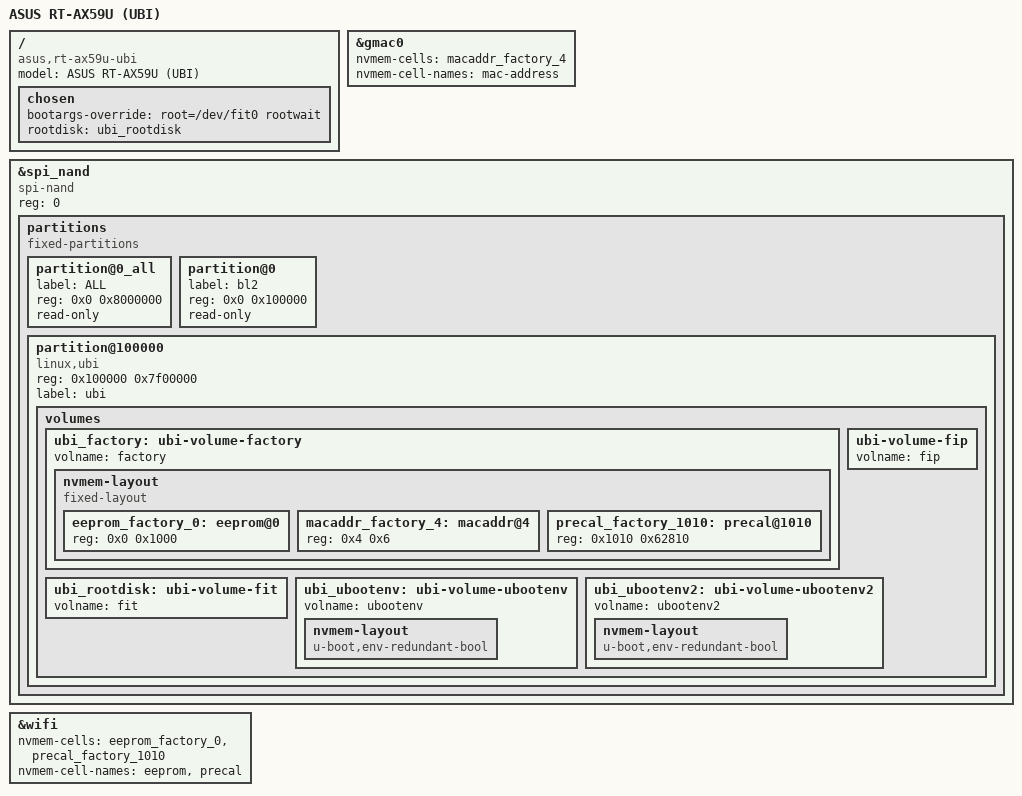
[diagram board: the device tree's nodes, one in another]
// SPDX-License-Identifier: (GPL-2.0 OR MIT)

#include "mt7986a-asus-rt-ax59u-common.dtsi"

/ {
	model = "ASUS RT-AX59U (UBI)";
	compatible = "asus,rt-ax59u-ubi", "mediatek,mt7986a";

	chosen {
		bootargs-override = "root=/dev/fit0 rootwait";
		rootdisk = <&ubi_rootdisk>;
	};
};

&gmac0 {
	nvmem-cells = <&macaddr_factory_4>;
	nvmem-cell-names = "mac-address";
};

&spi_nand {
	compatible = "spi-nand";
	reg = <0>;

	partitions {
		compatible = "fixed-partitions";
		#address-cells = <1>;
		#size-cells = <1>;

		partition@0_all {
			label = "ALL";
			reg = <0x0 0x8000000>;
			read-only;
		};

		partition@0 {
			label = "bl2";
			reg = <0x0 0x100000>;
			read-only;
		};

		partition@100000 {
			reg = <0x100000 0x7f00000>;
			compatible = "linux,ubi";
			label = "ubi";

			volumes {
				ubi_factory: ubi-volume-factory {
					volname = "factory";
				};

				ubi-volume-fip {
					volname = "fip";
				};

				ubi_rootdisk: ubi-volume-fit {
					volname = "fit";
				};

				ubi_ubootenv: ubi-volume-ubootenv {
					volname = "ubootenv";
				};

				ubi_ubootenv2: ubi-volume-ubootenv2 {
					volname = "ubootenv2";
				};
			};
		};
	};
};

&ubi_factory {
	nvmem-layout {
		compatible = "fixed-layout";
		#address-cells = <1>;
		#size-cells = <1>;

		eeprom_factory_0: eeprom@0 {
			reg = <0x0 0x1000>;
		};

		macaddr_factory_4: macaddr@4 {
			reg = <0x4 0x6>;
		};

		precal_factory_1010: precal@1010 {
			reg = <0x1010 0x62810>;
		};
	};
};

&ubi_ubootenv {
	nvmem-layout {
		compatible = "u-boot,env-redundant-bool";
	};
};

&ubi_ubootenv2 {
	nvmem-layout {
		compatible = "u-boot,env-redundant-bool";
	};
};

&wifi {
	nvmem-cells = <&eeprom_factory_0>, <&precal_factory_1010>;
	nvmem-cell-names = "eeprom", "precal";
};
